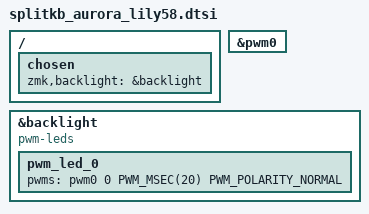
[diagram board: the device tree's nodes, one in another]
/ {
    chosen {
        zmk,backlight = &backlight;
    };
};

&pwm0 {
    status = "okay";
};

&backlight {
    compatible = "pwm-leds";
    pwm_led_0 {
        pwms = <&pwm0 0 PWM_MSEC(20) PWM_POLARITY_NORMAL>;
    };
};
